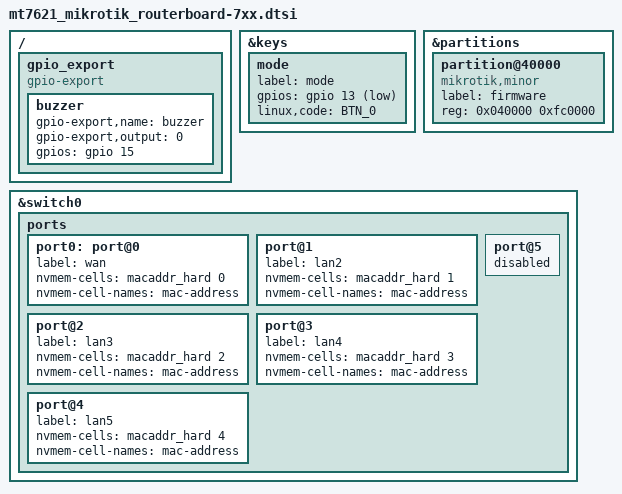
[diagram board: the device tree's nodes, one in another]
// SPDX-License-Identifier: GPL-2.0-or-later OR MIT

#include "mt7621_mikrotik.dtsi"

/ {
	gpio_export {
		compatible = "gpio-export";

		buzzer {
			/* Beeper requires PWM for frequency selection */
			gpio-export,name = "buzzer";
			gpio-export,output = <0>;
			gpios = <&gpio 15 GPIO_ACTIVE_HIGH>;
		};
	};
};

&keys {
	mode {
		label = "mode";
		gpios = <&gpio 13 GPIO_ACTIVE_LOW>;
		linux,code = <BTN_0>;
	};
};

&partitions {
	partition@40000 {
		compatible = "mikrotik,minor";
		label = "firmware";
		reg = <0x040000 0xfc0000>;
	};
};

&switch0 {
	ports {
		port0: port@0 {
			status = "okay";
			label = "wan";			nvmem-cells = <&macaddr_hard 0>;
			nvmem-cell-names = "mac-address";
		};

		port@1 {
			status = "okay";
			label = "lan2";

			nvmem-cells = <&macaddr_hard 1>;
			nvmem-cell-names = "mac-address";
		};

		port@2 {
			status = "okay";
			label = "lan3";

			nvmem-cells = <&macaddr_hard 2>;
			nvmem-cell-names = "mac-address";
		};

		port@3 {
			status = "okay";
			label = "lan4";

			nvmem-cells = <&macaddr_hard 3>;
			nvmem-cell-names = "mac-address";
		};

		port@4 {
			status = "okay";
			label = "lan5";

			nvmem-cells = <&macaddr_hard 4>;
			nvmem-cell-names = "mac-address";
		};

		/* RB750Gr3: solo gmac0 es cpu port (trgmii). port5 (gmac1 rgmii)
		 * del mt7621.dtsi base queda sin conectar — deshabilitarlo evita
		 * un segundo master DSA que confunde al driver eth. */
		port@5 {
			status = "disabled";
		};
	};
};
